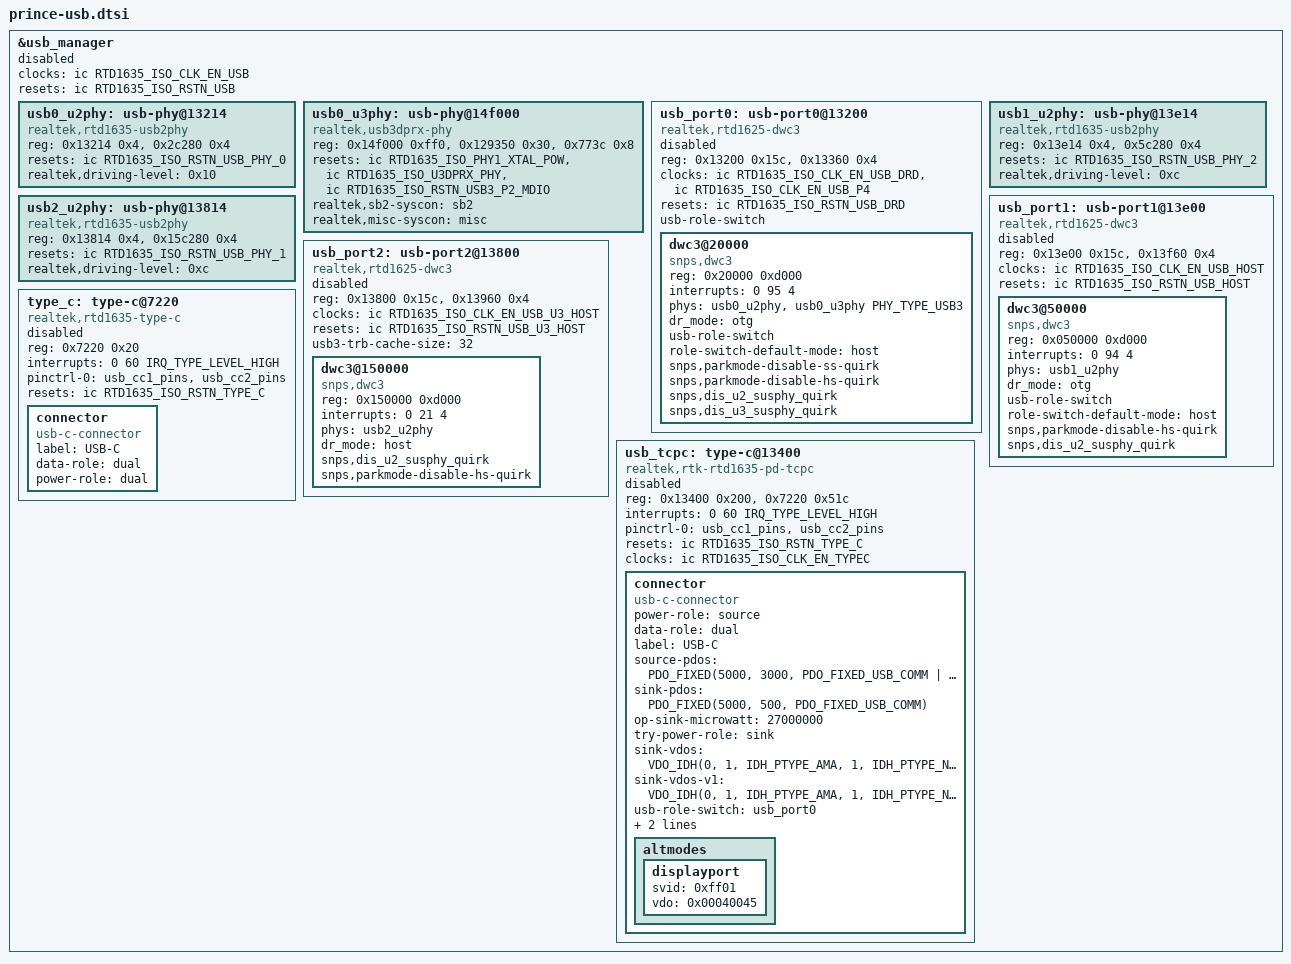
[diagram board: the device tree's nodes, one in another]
// SPDX-License-Identifier: (GPL-2.0-or-later OR BSD-2-Clause)
/*
 * Realtek Kent SoC USB
 *
 * Copyright (c) 2024 Realtek Semiconductor Corp.
 */
#include <dt-bindings/phy/phy.h>

#include <dt-bindings/usb/pd.h>

&usb_manager {
	clocks = <&ic RTD1635_ISO_CLK_EN_USB>; /* clk_en_usb */
	clock-names = "usb"; /*clk_en_usb*/

	resets = <&ic RTD1635_ISO_RSTN_USB>; /* rstn_usb */
	reset-names = "usb"; /* rstn_usb */

	status = "disabled";

	usb0_u2phy: usb-phy@13214 {
		compatible = "realtek,rtd1635-usb2phy";
		reg = <0x13214 0x4>, <0x2c280 0x4>;
		#phy-cells = <0>;
		//nvmem-cells = <&otp_usb_port0_dc_cal>, <&otp_usb_port0_dc_dis>;
		//nvmem-cell-names = "usb-dc-cal", "usb-dc-dis";

		resets = <&ic RTD1635_ISO_RSTN_USB_PHY_0>; /* rstn_usb_phy0 (port0 u2phy) */
		reset-names = "u2phy"; /* rstn_usb_phy0 (port0 u2phy) */
		realtek,driving-level = <0x10>;
	};

	usb0_u3phy: usb-phy@14f000 {
		compatible = "realtek,usb3dprx-phy";
		reg = <0x14f000 0xff0>, <0x129350 0x30>, <0x773c 0x8>;
		#phy-cells = <1>;
		//nvmem-cells = <&otp_usb_port0_u3_tx_lfps_swing_trim>;
		//nvmem-cell-names = "usb_port0_u3_tx_lfps_swing_trim";

		resets = <&ic RTD1635_ISO_PHY1_XTAL_POW>,
			<&ic RTD1635_ISO_U3DPRX_PHY>,
			<&ic RTD1635_ISO_RSTN_USB3_P2_MDIO>; /* rstn_usb3_phy1_mdio (port0 u3phy) */
		reset-names = "u3phy", /* rstn_usb3_phy0 (port0 u3phy) */
			      "u3dprx",
			      "u3mdio"; /* rstn_usb3_phy0_mdio (port0 u3phy) */
		realtek,sb2-syscon = <&sb2>;
		realtek,misc-syscon = <&misc>;
	};

	usb_port0: usb-port0@13200 {
		compatible = "realtek,rtd1625-dwc3", "realtek,dwc3";
		reg = <0x13200 0x15c>, <0x13360 0x4>;
		#address-cells = <1>;
		#size-cells = <1>;
		ranges;

		clocks = <&ic RTD1635_ISO_CLK_EN_USB_DRD>, /* clk_en_usb_drd (port0 phy to u2drd clock) */
			<&ic RTD1635_ISO_CLK_EN_USB_P4>;
		clock-names = "usb-mac", /* clk_en_usb_drd (port0 phy to u2drd clock) */
				"usb-u3";
		resets = <&ic RTD1635_ISO_RSTN_USB_DRD>; /* rstn_usb_u2drd (port0) */
		reset-names = "usb-mac"; /* rstn_usb_u2drd (port0) */

		//realtek,power-gpio = <&gpio 48 GPIO_ACTIVE_LOW>;
		status = "disabled";

		usb-role-switch;

		dwc3@20000 {
			compatible = "snps,dwc3";
			reg = <0x20000 0xd000>;
			interrupts = <0 95 4>;
			phys = <&usb0_u2phy>, <&usb0_u3phy PHY_TYPE_USB3>;
			phy-names = "usb2-phy", "usb3-phy";
			dr_mode = "otg";
			usb-role-switch;
			role-switch-default-mode = "host"; /* host, peripheral*/
			snps,parkmode-disable-ss-quirk; // disable usb3.0 park mode
			snps,parkmode-disable-hs-quirk; // disable usb2.0 park mode
			snps,dis_u2_susphy_quirk; // Disable u2phy suspend for drd
			snps,dis_u3_susphy_quirk; // Disable u3phy suspend for drd
		};
	};

	usb1_u2phy: usb-phy@13e14 {
		compatible = "realtek,rtd1635-usb2phy";
		reg = <0x13e14 0x4>, <0x5c280 0x4>;
		#phy-cells = <0>;
		//nvmem-cells = <&otp_usb_port1_dc_cal>, <&otp_usb_port1_dc_dis>;
		//nvmem-cell-names = "usb-dc-cal", "usb-dc-dis";

		resets = <&ic RTD1635_ISO_RSTN_USB_PHY_2>; /* rstn_usb_phy1 (port1 u2phy) */
		reset-names = "u2phy"; /* rstn_usb_phy1 (port1 u2phy) */
		realtek,driving-level = <0xc>;
	};

	usb_port1: usb-port1@13e00 {
		compatible = "realtek,rtd1625-dwc3", "realtek,dwc3";
		reg = <0x13e00 0x15c>, <0x13f60 0x4>;
		#address-cells = <1>;
		#size-cells = <1>;
		ranges;

		clocks = <&ic RTD1635_ISO_CLK_EN_USB_HOST>;  /* clk_en_usb_host0 (port1 phy to u2host clock) */
		clock-names = "usb-mac"; /* clk_en_usb_u2host (port1 phy to u2host clock) */
		resets = <&ic RTD1635_ISO_RSTN_USB_HOST>; /* rstn_usb_u3drd (port1) */
		reset-names = "usb-mac"; /* rstn_usb_u3drd (port1) */

		//realtek,power-gpio = <&gpio 48 GPIO_ACTIVE_LOW>;

		status = "disabled";

		dwc3@50000 {
			compatible = "snps,dwc3";
			reg = <0x050000 0xd000>;
			interrupts = <0 94 4>;
			phys = <&usb1_u2phy>;
			phy-names = "usb2-phy";
			dr_mode = "otg";
			usb-role-switch;
			role-switch-default-mode = "host"; /* host, peripheral*/
			snps,parkmode-disable-hs-quirk; // disable usb2.0 park mode
			snps,dis_u2_susphy_quirk; // Disable u2phy suspend for drd
		};
	};

	usb2_u2phy: usb-phy@13814 {
		compatible = "realtek,rtd1635-usb2phy";
		reg = <0x13814 0x4>, <0x15c280 0x4>;
		#phy-cells = <0>;
		//nvmem-cells = <&otp_usb_port2_dc_cal>, <&otp_usb_port2_dc_dis>;
		//nvmem-cell-names = "usb-dc-cal", "usb-dc-dis";

		resets = <&ic RTD1635_ISO_RSTN_USB_PHY_1>; /* rstn_usb_phy2 (port2 u2phy) */
		reset-names = "u2phy"; /* rstn_usb_phy2 (port2 u2phy) */
		realtek,driving-level = <0xc>;
	};

	usb_port2: usb-port2@13800 {
		compatible = "realtek,rtd1625-dwc3", "realtek,dwc3";
		reg = <0x13800 0x15c>, <0x13960 0x4>;
		#address-cells = <1>;
		#size-cells = <1>;
		ranges;

		clocks = <&ic RTD1635_ISO_CLK_EN_USB_U3_HOST>;  /* clk_en_usb_host1 (port2 phy to u3drd clock) */
		clock-names = "usb-mac"; /* clk_en_usb_u3host (port2 phy to u3drd clock) */
		resets = <&ic RTD1635_ISO_RSTN_USB_U3_HOST>; /* rstn_usb_u2host(port2) */
		reset-names = "usb-mac"; /* rstn_usb_u2host (port2) */

		//realtek,power-gpio = <&gpio 49 GPIO_ACTIVE_LOW>;

		usb3-trb-cache-size = <32>; /* for xhci controller */

		status = "disabled";

		dwc3@150000 {
			compatible = "snps,dwc3";
			reg = <0x150000 0xd000>;
			interrupts = <0 21 4>;
			phys = <&usb2_u2phy>;
			phy-names = "usb2-phy";
			dr_mode = "host";
			snps,dis_u2_susphy_quirk; // Disable u2phy suspend for drd
			snps,parkmode-disable-hs-quirk; // disable usb2.0 park mode
		};
	};

	type_c: type-c@7220 {
		compatible = "realtek,rtd1635-type-c";
		reg = <0x7220 0x20>;
		#address-cells = <1>;
		#size-cells = <1>;
		ranges;

		interrupts = <0 60 IRQ_TYPE_LEVEL_HIGH>;

		//realtek,usb-port = <&usb_port0>;

		pinctrl-names = "default";
		pinctrl-0 = <&usb_cc1_pins>, <&usb_cc2_pins>;

		//nvmem-cells = <&otp_usb_type_c_cal>;
		//nvmem-cell-names = "usb-type-c-cal";

		resets = <&ic RTD1635_ISO_RSTN_TYPE_C>; /* rstn_type_c */
		reset-names = "type-c"; /* rstn_type_c */

		//realtek,vbus-ctrl-gpio = <&gpio 126 GPIO_ACTIVE_LOW>;
		//realtek,vconn1-en-gpio = <&gpio 108 GPIO_ACTIVE_HIGH>;
		//realtek,vconn2-en-gpio = <&gpio 109 GPIO_ACTIVE_HIGH>;

		status = "disabled";

		connector {
			compatible = "usb-c-connector";
			label = "USB-C";
			data-role = "dual";
			power-role = "dual";
		};
	};

	usb_tcpc: type-c@13400 {
		compatible = "realtek,rtk-rtd1635-pd-tcpc";
		reg = <0x13400 0x200>, <0x7220 0x51c>;
		reg-names = "pd", "typec";
		#address-cells = <1>;
		#size-cells = <1>;
		ranges;

		interrupts = <0 60 IRQ_TYPE_LEVEL_HIGH>;

		pinctrl-names = "default";
		pinctrl-0 = <&usb_cc1_pins>, <&usb_cc2_pins>;

		//nvmem-cells = <&otp_usb_type_c_cal>;
		//nvmem-cell-names = "usb-type-c-cal";

		resets = <&ic RTD1635_ISO_RSTN_TYPE_C>; /* rstn_type_c */
		reset-names = "type-c"; /* rstn_type_c */
		clocks = <&ic RTD1635_ISO_CLK_EN_TYPEC>;
		clock-names = "type-c";

		/* gpios are defined in board level */
		//vbus-en-gpio = <&gpio 126 GPIO_ACTIVE_LOW>;
		//vconn1-en-gpio = <&gpio 108 GPIO_ACTIVE_HIGH>;
		//vconn2-en-gpio = <&gpio 109 GPIO_ACTIVE_HIGH>;

		status = "disabled";

		connector {
			compatible = "usb-c-connector";
			power-role = "source";//"dual";
			data-role = "dual";
			label = "USB-C";
			source-pdos =
				<PDO_FIXED(5000, 3000, PDO_FIXED_USB_COMM |
					PDO_FIXED_DUAL_ROLE | PDO_FIXED_DATA_SWAP)
				 PDO_FIXED(9000, 2500, 0)>;
				//<PDO_FIXED(5000, 1500, PDO_FIXED_USB_COMM |
				//	PDO_FIXED_DUAL_ROLE | PDO_FIXED_DATA_SWAP)>;
			sink-pdos =
				<PDO_FIXED(5000, 500, PDO_FIXED_USB_COMM)>;
			op-sink-microwatt = <27000000>; /* 27W = 9V * 3A */
			try-power-role = "sink";

			sink-vdos = <VDO_IDH(0, 1, IDH_PTYPE_AMA, 1, IDH_PTYPE_NOT_DFP, 0, 0x0bda)
				     VDO_CERT(0)
				     VDO_PRODUCT(0x1234, 0x0100)
				     VDO_UFP(UFP_VDO_VER1_2, (DEV_USB2_CAPABLE | DEV_USB3_CAPABLE), UFP_RECEPTACLE, 0, 0, 0, UFP_ALTMODE_RECFG, UFP_USB32_GEN1)>;

			sink-vdos-v1 = <VDO_IDH(0, 1, IDH_PTYPE_AMA, 1, IDH_PTYPE_NOT_DFP, 0, 0x0bda)
					VDO_CERT(0)
					VDO_PRODUCT(0x1234, 0x0100)>;

			usb-role-switch = <&usb_port0>;
			orientation-switch = <&usb0_u3phy>;
			mode-switch = <&usb0_u3phy>;

			/* Alt Mode support - DisplayPort */
			altmodes {
				displayport {
					svid = /bits/ 16 <0xff01>;  /* DisplayPort SVID */

					/* UFP_D pins = None, DFP_D pins = C */
					vdo = <0x00040045>;
				};
			};
		};
	};
};
